VERSION "0.1.0"

NS_ :

BS_:
BU_:
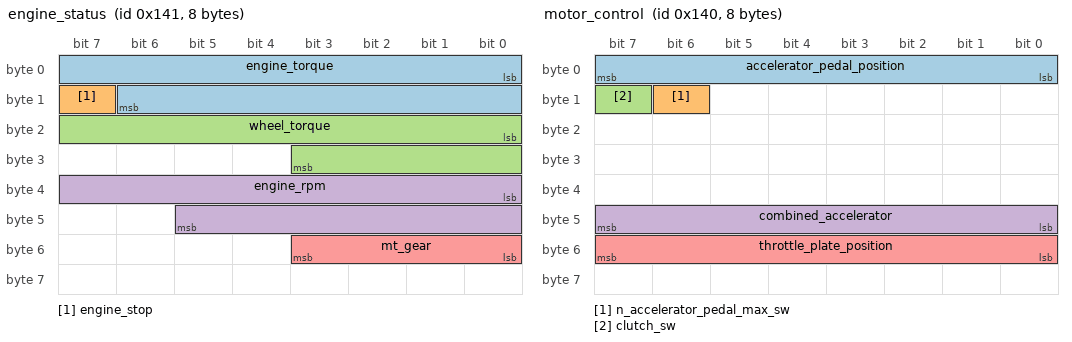
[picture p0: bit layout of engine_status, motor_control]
BO_ 321 engine_status: 8 Vector__XXX
   SG_ engine_torque : 0|15@1+ (1,0) [0|255] "" Vector__XXX
   SG_ engine_stop : 15|1@1+ (1,0) [0|1] "" Vector__XXX
   SG_ wheel_torque : 16|12@1+ (1,0) [0|4095] "" Vector__XXX
   SG_ engine_rpm : 32|14@1+ (1,0) [0|8191] "RPM" Vector__XXX
   SG_ mt_gear : 48|4@1+ (1,0) [0|7] "" Vector__XXX

BO_ 208 g_sensor: 8 Vector__XXX
   SG_ g_sensor_lateral : 16|16@1- (-0.0035,1) [-255|255] "" Vector__XXX
   SG_ g_sensor_longitudinal : 48|16@1- (-0.0035,1) [-255|255] "" Vector__XXX

BO_ 209 XXXMsg209: 4 Vector__XXX
   SG_ vehicle_speed : 0|16@1+ (0.05625,0) [0|290] "KPH" Vector__XXX
   SG_ brake_pedal_pressure : 16|8@1+ (0.78125,0) [0|100] "%" Vector__XXX

BO_ 328 transmission: 8 Vector__XXX
   SG_ mt_gear_VERIFY : 4|4@1+ (1,0) [0|7] "" Vector__XXX

BO_ 320 motor_control: 8 Vector__XXX
   SG_ accelerator_pedal_position : 0|8@1+ (0.392157,0) [0|1] "%" Vector__XXX
   SG_ n_accelerator_pedal_max_sw : 14|1@1+ (1,0) [0|1] "" Vector__XXX
   SG_ clutch_sw : 15|1@0+ (1,0) [0|1] "" Vector__XXX
   SG_ combined_accelerator : 40|8@1+ (0.392157,0) [0|100] "%" Vector__XXX
   SG_ throttle_plate_position : 48|8@1+ (0.392157,0) [0|100] "%" Vector__XXX

BO_ 282 steering: 8 Vector__XXX
   SG_ steering_angle : 56|8@1- (0.1,0) [-500|500] "degree" Vector__XXX

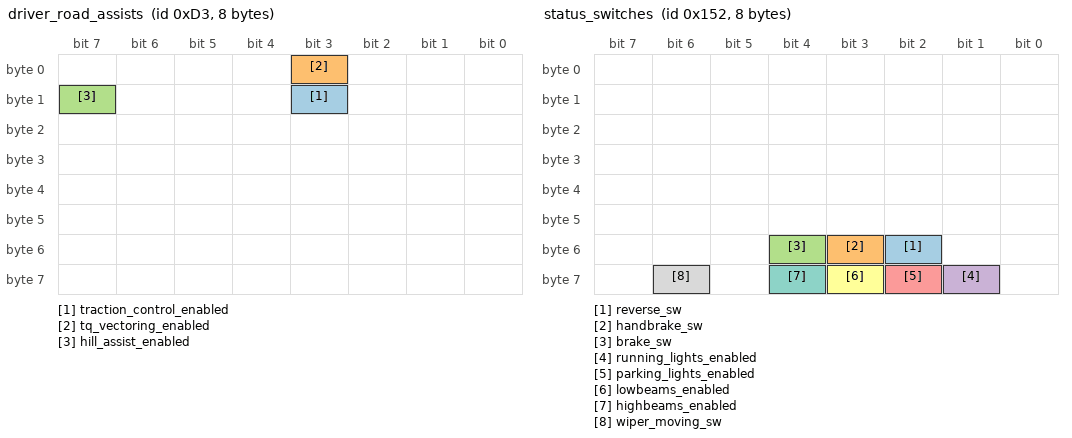
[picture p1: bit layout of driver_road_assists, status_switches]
BO_ 211 driver_road_assists: 8 Vector__XXX
   SG_ traction_control_enabled : 11|1@0+ (-1,1) [0|1] "" Vector__XXX
   SG_ tq_vectoring_enabled : 3|1@0+ (1,0) [0|1] "" Vector__XXX
   SG_ hill_assist_enabled : 15|1@0+ (1,0) [0|1] "" Vector__XXX

BO_ 338 status_switches: 8 Vector__XXX
   SG_ reverse_sw : 50|1@0+ (1,0) [0|1] "" Vector__XXX
   SG_ handbrake_sw : 51|1@0+ (1,0) [0|1] "" Vector__XXX
   SG_ brake_sw : 52|1@0+ (1,0) [0|1] "" Vector__XXX
   SG_ running_lights_enabled : 57|1@0+ (1,0) [0|1] "" Vector__XXX
   SG_ parking_lights_enabled : 58|1@0+ (1,0) [0|1] "" Vector__XXX
   SG_ lowbeams_enabled : 59|1@0+ (1,0) [0|1] "" Vector__XXX
   SG_ highbeams_enabled : 60|1@0+ (1,0) [0|1] "" Vector__XXX
   SG_ wiper_moving_sw : 62|1@1+ (1,0) [0|1] "" Vector__XXX

BO_ 340 XXXMsg340: 8 Vector__XXX
   SG_ any_door_open : 48|1@0+ (1,0) [0|1] "" Vector__XXX

BO_ 642 XXXMsg640: 8 Vector__XXX
   SG_ fuel_level : 0|12@1+ (0.033,0) [0|100] "%" Vector__XXX
   SG_ raw_fuel : 0|12@1+ (1,0) [0|4096] "%" Vector__XXX
   SG_ left_turn_signal_enabled : 44|1@0+ (1,0) [0|1] "" Vector__XXX
   SG_ right_turn_signal_enabled : 45|1@0+ (1,0) [0|1] "" Vector__XXX
   SG_ driver_seatbelt_warning_enabled : 40|1@0+ (1,0) [0|1] "" Vector__XXX

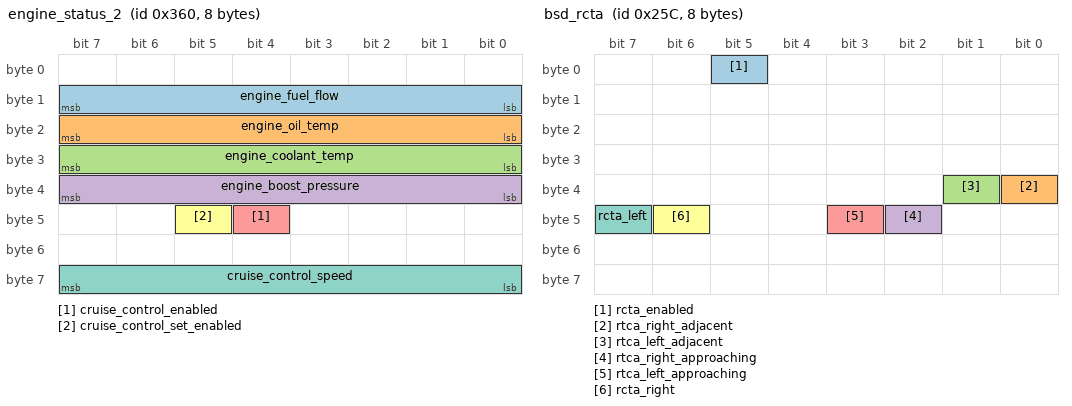
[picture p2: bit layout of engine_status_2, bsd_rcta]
BO_ 864 engine_status_2: 8 Vector__XXX
   SG_ engine_fuel_flow : 8|8@1+ (1,0) [0|255] "" Vector__XXX
   SG_ engine_oil_temp : 16|8@1+ (1,-40) [0|1] "degC" Vector__XXX
   SG_ engine_coolant_temp : 24|8@1+ (1,-40) [0|1] "degC" Vector__XXX
   SG_ engine_boost_pressure : 32|8@1- (0.3,-15.1) [0|255] "psi" Vector__XXX
   SG_ cruise_control_enabled : 44|1@0+ (1,0) [0|1] "" Vector__XXX
   SG_ cruise_control_set_enabled : 45|1@0+ (1,0) [0|1] "" Vector__XXX
   SG_ cruise_control_speed : 56|8@1+ (1,0) [0|255] "" Vector__XXX

BO_ 604 bsd_rcta: 8 Vector__XXX
   SG_ rcta_enabled : 5|1@1+ (1,0) [0|1] "" Vector__XXX
   SG_ rtca_right_adjacent : 32|1@1+ (1,0) [0|1] "" Vector__XXX
   SG_ rtca_left_adjacent : 33|1@1+ (1,0) [0|1] "" Vector__XXX
   SG_ rtca_right_approaching : 42|1@1+ (1,0) [0|1] "" Vector__XXX
   SG_ rtca_left_approaching : 43|1@1+ (1,0) [0|1] "" Vector__XXX
   SG_ rcta_right : 46|1@1+ (1,0) [0|1] "" Vector__XXX
   SG_ rcta_left : 47|1@1+ (1,0) [0|1] "" Vector__XXX

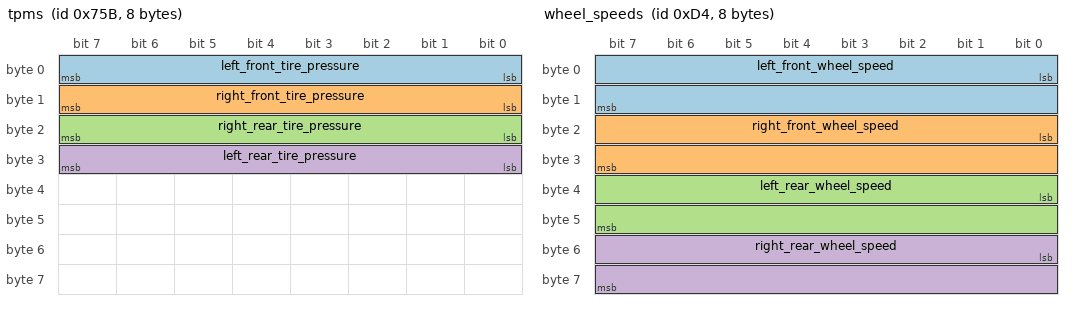
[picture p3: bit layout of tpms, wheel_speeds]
BO_ 1883 tpms: 8 Vector__XXX
   SG_ left_front_tire_pressure : 0|8@1+ (1,0) [0|1] "" Vector__XXX
   SG_ right_front_tire_pressure : 8|8@1+ (1,0) [0|1] "" Vector__XXX
   SG_ right_rear_tire_pressure : 16|8@1+ (1,0) [0|1] "" Vector__XXX
   SG_ left_rear_tire_pressure : 24|8@1+ (1,0) [0|1] "" Vector__XXX

BO_ 1745 odometer: 8 Vector__XXX
   SG_ odometer : 0|32@1+ (0.1,0) [0|4294967300] "" Vector__XXX

BO_ 977 Dash_State2_VERIFY: 8 Vector__XXX
   SG_ UNITS : 15|1@1+ (1,0) [0|1] "" Vector__XXX

BO_ 212 wheel_speeds: 8 Vector__XXX
   SG_ left_front_wheel_speed : 0|16@1+ (0.0592,0) [0|255] "KPH" Vector__XXX
   SG_ right_front_wheel_speed : 16|16@1+ (0.0592,0) [0|255] "KPH" Vector__XXX
   SG_ left_rear_wheel_speed : 32|16@1+ (0.0592,0) [0|255] "KPH" Vector__XXX
   SG_ right_rear_wheel_speed : 48|16@1+ (0.0592,0) [0|255] "KPH" Vector__XXX

BO_ 865 engine_warning_lights: 8 Vector__XXX
   SG_ oil_pressure_warning_light_enabled : 12|1@0+ (1,0) [0|1] "" Vector__XXX
   SG_ check_engine_light_enabled : 39|1@0+ (1,0) [0|1] "" Vector__XXX

BO_ 882 srs_status: 8 Vector__XXX
   SG_ srs_system_warning_light_enabled : 16|1@0+ (1,0) [0|1] "" Vector__XXX

BO_ 884 XXXMsg884: 8 Vector__XXX
   SG_ fog_lights_enabled : 14|1@0+ (1,0) [0|1] "" Vector__XXX
   SG_ tpms_warning_light_enabled : 36|1@0+ (1,0) [0|1] "" Vector__XXX

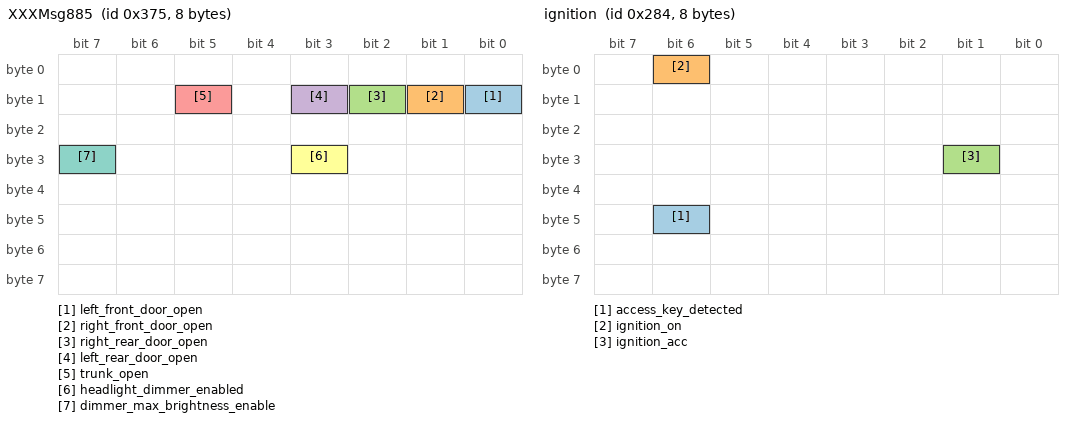
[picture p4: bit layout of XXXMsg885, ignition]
BO_ 885 XXXMsg885: 8 Vector__XXX
   SG_ left_front_door_open : 8|1@0+ (1,0) [0|1] "" Vector__XXX
   SG_ right_front_door_open : 9|1@0+ (1,0) [0|1] "" Vector__XXX
   SG_ right_rear_door_open : 10|1@0+ (1,0) [0|1] "" Vector__XXX
   SG_ left_rear_door_open : 11|1@0+ (1,0) [0|1] "" Vector__XXX
   SG_ trunk_open : 13|1@0+ (1,0) [0|1] "" Vector__XXX
   SG_ headlight_dimmer_enabled : 27|1@0+ (1,0) [0|1] "" Vector__XXX
   SG_ dimmer_max_brightness_enable : 31|1@0+ (1,0) [0|1] "" Vector__XXX

BO_ 886 DimmerAndHood: 8 Vector__XXX
   SG_ dimmer_dial_value : 0|8@1+ (1,0) [0|250] "" Vector__XXX
   SG_ hood_closed : 8|1@1+ (1,0) [0|1] "" Vector__XXX

BO_ 644 ignition: 8 Vector__XXX
   SG_ access_key_detected : 46|1@0+ (-1,0) [0|1] "" Vector__XXX
   SG_ ignition_on : 6|1@0+ (1,0) [0|1] "" Vector__XXX
   SG_ ignition_acc : 25|1@0+ (1,0) [0|1] "" Vector__XXX

CM_ SG_ 320 n_accelerator_pedal_max_sw "is 0 when pressed NOT VERIFIED";
CM_ SG_ 642 fuel_level "need_to_verify_min/max/scale";
CM_ SG_ 864 engine_fuel_flow "scale/unit_undetermined";
CM_ SG_ 864 engine_boost_pressure "need_to_verify";
CM_ SG_ 864 cruise_control_speed "unit_is_determined_by_vehicle_region_or_bit_flag";
CM_ BO_ 1883 "no successful communication with bcm yet";
CM_ SG_ 1883 left_front_tire_pressure "scale/unit_undetermined";
CM_ SG_ 1883 right_front_tire_pressure "scale/unit_undetermined";
CM_ SG_ 1883 right_rear_tire_pressure "scale/unit_undetermined";
CM_ SG_ 1883 left_rear_tire_pressure "scale/unit_undetermined";
CM_ SG_ 1745 odometer "unit_determined_by_vehicle_region";
CM_ SG_ 977 UNITS "0 = Metric, 1 = Imperial NOT VERIFIED";
CM_ SG_ 644 access_key_detected "4:6_bits_are_set_but_only_check_6";
BA_DEF_ BO_ "GenMsgBackgroundColor" STRING ;
BA_DEF_ BO_ "GenMsgForegroundColor" STRING ;
BA_DEF_ BO_ "filterlabeling" INT 0 0;
BA_DEF_ BO_ "filterlabeling" INT 0 0;
BA_DEF_DEF_ "GenMsgBackgroundColor" "#1b1e20";
BA_DEF_DEF_ "GenMsgForegroundColor" "#fcfcfc";
BA_DEF_DEF_ "filterlabeling" 1;
BA_DEF_DEF_ "filterlabeling" 1;
BA_ "GenMsgForegroundColor" BO_ 321 "#00aa00";
BA_ "GenMsgForegroundColor" BO_ 209 "#00aa00";
BA_ "GenMsgForegroundColor" BO_ 320 "#00aa00";
BA_ "GenMsgForegroundColor" BO_ 282 "#00aa00";
BA_ "GenMsgForegroundColor" BO_ 211 "#00aa00";
BA_ "GenMsgForegroundColor" BO_ 338 "#00aa00";
BA_ "GenMsgForegroundColor" BO_ 340 "#00aa00";
BA_ "GenMsgForegroundColor" BO_ 642 "#00aa00";
BA_ "GenMsgForegroundColor" BO_ 864 "#000000";
BA_ "GenMsgForegroundColor" BO_ 1883 "#00aa00";
BA_ "GenMsgForegroundColor" BO_ 1745 "#00aa00";
BA_ "GenMsgForegroundColor" BO_ 212 "#00aa00";
BA_ "GenMsgForegroundColor" BO_ 644 "#00aa00";
VAL_ 321 mt_gear 0 "FLOATING" 1 "1" 2 "2" 3 "3" 4 "4" 5 "5" 6 "6" 7 "NEUTRAL";
VAL_ 886 dimmer_dial_value 0 "0" 33 "1" 82 "2" 125 "3" 173 "4" 250 "5";
